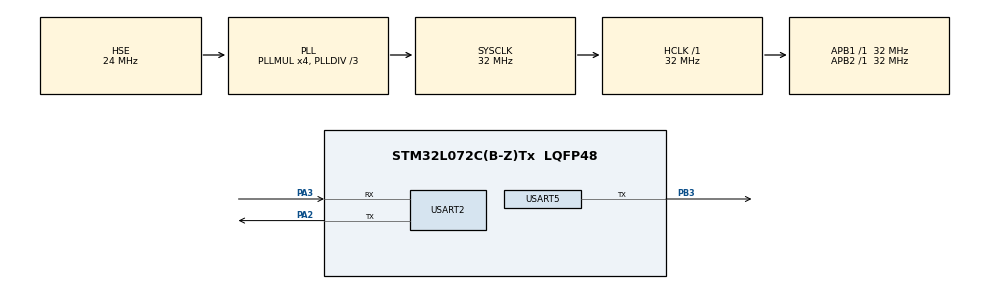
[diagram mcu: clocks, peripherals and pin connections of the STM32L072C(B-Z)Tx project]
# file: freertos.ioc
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Dma.Request0=USART2_RX
Dma.Request1=USART2_TX
Dma.Request2=USART5_TX
Dma.USART2_RX.0.Direction=DMA_PERIPH_TO_MEMORY
Dma.USART2_RX.0.Instance=DMA1_Channel5
Dma.USART2_RX.0.MemDataAlignment=DMA_MDATAALIGN_BYTE
Dma.USART2_RX.0.MemInc=DMA_MINC_ENABLE
Dma.USART2_RX.0.Mode=DMA_CIRCULAR
Dma.USART2_RX.0.PeriphDataAlignment=DMA_PDATAALIGN_BYTE
Dma.USART2_RX.0.PeriphInc=DMA_PINC_DISABLE
Dma.USART2_RX.0.Priority=DMA_PRIORITY_LOW
Dma.USART2_TX.1.Direction=DMA_MEMORY_TO_PERIPH
Dma.USART2_TX.1.Instance=DMA1_Channel4
Dma.USART2_TX.1.MemDataAlignment=DMA_MDATAALIGN_BYTE
Dma.USART2_TX.1.MemInc=DMA_MINC_ENABLE
Dma.USART2_TX.1.Mode=DMA_NORMAL
Dma.USART2_TX.1.PeriphDataAlignment=DMA_PDATAALIGN_BYTE
Dma.USART2_TX.1.PeriphInc=DMA_PINC_DISABLE
Dma.USART2_TX.1.Priority=DMA_PRIORITY_LOW
Dma.USART5_TX.2.Direction=DMA_MEMORY_TO_PERIPH
Dma.USART5_TX.2.Instance=DMA1_Channel3
Dma.USART5_TX.2.MemDataAlignment=DMA_MDATAALIGN_BYTE
Dma.USART5_TX.2.MemInc=DMA_MINC_ENABLE
Dma.USART5_TX.2.Mode=DMA_NORMAL
Dma.USART5_TX.2.PeriphDataAlignment=DMA_PDATAALIGN_BYTE
Dma.USART5_TX.2.PeriphInc=DMA_PINC_DISABLE
Dma.USART5_TX.2.Priority=DMA_PRIORITY_LOW
FREERTOS.BinarySemaphores01=sockfd_sem,Dynamic,NULL,Available
FREERTOS.Tasks01=defaultTask,24,288,StartDefaultTask,Default,NULL,Dynamic,NULL,NULL;publisherTask,24,256,StartPublisherTask,Default,NULL,Dynamic,NULL,NULL
FREERTOS.configGENERATE_RUN_TIME_STATS=1
FREERTOS.configRECORD_STACK_HIGH_ADDRESS=1
FREERTOS.configTOTAL_HEAP_SIZE=12288
FREERTOS.configUSE_STATS_FORMATTING_FUNCTIONS=1
Mcu.Family=STM32L0
Mcu.Name=STM32L072C(B-Z)Tx
Mcu.Package=LQFP48
NVIC.DMA1_Channel2_3_IRQn=true\:3\:0\:false\:false\:true\:true\:false\:true\:true
NVIC.DMA1_Channel4_5_6_7_IRQn=true\:3\:0\:false\:false\:true\:true\:false\:true\:true
NVIC.TIM2_IRQn=true\:3\:0\:false\:false\:true\:false\:false\:true\:true
NVIC.TimeBase=TIM2_IRQn
NVIC.TimeBaseIP=TIM2
NVIC.USART2_IRQn=true\:3\:0\:false\:false\:true\:true\:false\:true\:true
NVIC.USART4_5_IRQn=true\:3\:0\:false\:false\:true\:true\:true\:true\:true
PA2.Mode=Asynchronous
PA2.Signal=USART2_TX
PA3.Mode=Asynchronous
PA3.Signal=USART2_RX
PB3.Mode=Half_duplex(single_wire_mode)
PB3.Signal=USART5_TX
PH0-OSC_IN.Mode=HSE-External-Oscillator
PH0-OSC_IN.Signal=RCC_OSC_IN
PH1-OSC_OUT.Mode=HSE-External-Oscillator
PH1-OSC_OUT.Signal=RCC_OSC_OUT
ProjectManager.HeapSize=0x200
ProjectManager.StackSize=0x400
ProjectManager.TargetToolchain=CMake
RCC.AHBFreq_Value=32000000
RCC.APB1Freq_Value=32000000
RCC.APB1TimFreq_Value=32000000
RCC.APB2Freq_Value=32000000
RCC.APB2TimFreq_Value=32000000
RCC.HCLKFreq_Value=32000000
RCC.HSE_VALUE=24000000
RCC.HSI16_VALUE=16000000
RCC.HSI48_VALUE=48000000
RCC.HSI_VALUE=16000000
RCC.LSE_VALUE=32768
RCC.MSI_VALUE=2097000
RCC.PLLDIV=RCC_PLLDIV_3
RCC.PLLMUL=RCC_PLLMUL_4
RCC.PLLSourceVirtual=RCC_PLLSOURCE_HSE
RCC.SYSCLKFreq_VALUE=32000000
RCC.SYSCLKSource=RCC_SYSCLKSOURCE_PLLCLK
RCC.VCOOutputFreq_Value=96000000
USART2.VirtualMode-Asynchronous=VM_ASYNC
USART5.Mode=MODE_TX
USART5.VirtualMode-Half_duplex(single_wire_mode)=VM_ASYNC
VP_FREERTOS_VS_CMSIS_V2.Mode=CMSIS_V2
VP_SYS_VS_tim2.Mode=TIM2
board=custom

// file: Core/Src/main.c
/* USER CODE BEGIN Header */
/**
 ******************************************************************************
 * @file           : main.c
 * @brief          : Main program body
 ******************************************************************************
 * @attention
 *
 * Copyright (c) 2025 STMicroelectronics.
 * All rights reserved.
 *
 * This software is licensed under terms that can be found in the LICENSE file
 * in the root directory of this software component.
 * If no LICENSE file comes with this software, it is provided AS-IS.
 *
 ******************************************************************************
 */
/* USER CODE END Header */
#include "main.h"
#include "cmsis_os.h"

/* USER CODE BEGIN Includes */
#include <stdio.h>
#include <string.h>
#include <stdlib.h>

#include "umodem.h"
#include "umodem_mqtt.h"
/* USER CODE END Includes */

UART_HandleTypeDef huart2;
UART_HandleTypeDef huart5;
DMA_HandleTypeDef hdma_usart2_rx;
DMA_HandleTypeDef hdma_usart2_tx;
DMA_HandleTypeDef hdma_usart5_tx;

/* Definitions for defaultTask */
osThreadId_t defaultTaskHandle;
const osThreadAttr_t defaultTask_attributes = {
  .name = "defaultTask",
  .stack_size = 288 * 4,
  .priority = (osPriority_t) osPriorityNormal,
};
/* Definitions for publisherTask */
osThreadId_t publisherTaskHandle;
const osThreadAttr_t publisherTask_attributes = {
  .name = "publisherTask",
  .stack_size = 256 * 4,
  .priority = (osPriority_t) osPriorityNormal,
};
/* Definitions for sockfd_sem */
osSemaphoreId_t sockfd_semHandle;
const osSemaphoreAttr_t sockfd_sem_attributes = {
  .name = "sockfd_sem"
};
/* USER CODE BEGIN PV */
static int sockfd = -1;
/* USER CODE END PV */

void SystemClock_Config(void);
static void MX_GPIO_Init(void);
static void MX_DMA_Init(void);
static void MX_USART2_UART_Init(void);
static void MX_USART5_UART_Init(void);
void StartDefaultTask(void *argument);
void StartPublisherTask(void *argument);

/* USER CODE BEGIN 0 */
static osSemaphoreId_t tx5_sem = NULL;
void HAL_UART5_TxCpltCallback(UART_HandleTypeDef *huart)
{
  if (huart->Instance == USART5)
    osSemaphoreRelease(tx5_sem); /* Release the semaphore after the DMA transfer is complete */
}

#ifdef __GNUC__
/* With GCC/RAISONANCE, small printf (option LD Linker->Libraries->Small printf
   set to 'Yes') calls __io_putchar() */
#define PUTCHAR_PROTOTYPE int __io_putchar(int ch)
#else
#define PUTCHAR_PROTOTYPE int fputc(int ch, FILE *f)
#endif /* __GNUC__ */

PUTCHAR_PROTOTYPE
{
  /* Place your implementation of fputc here */
  /* e.g. write a character to the USART5 and Loop until the end of transmission */
  osSemaphoreAcquire(tx5_sem, osWaitForever);
  HAL_UART_Transmit_DMA(&huart5, (uint8_t *)&ch, 1);

  return ch;
}
/* USER CODE END 0 */

int main(void)
{

  /* MCU Configuration--------------------------------------------------------*/

  /* Reset of all peripherals, Initializes the Flash interface and the Systick. */
  HAL_Init();

  /* Configure the system clock */
  SystemClock_Config();

  /* Initialize all configured peripherals */
  MX_GPIO_Init();
  MX_DMA_Init();
  MX_USART2_UART_Init();
  MX_USART5_UART_Init();

  /* Init scheduler */
  osKernelInitialize();

  /* Create the semaphores(s) */
  /* creation of sockfd_sem */
  sockfd_semHandle = osSemaphoreNew(1, 1, &sockfd_sem_attributes);

  /* Create the thread(s) */
  /* creation of defaultTask */
  defaultTaskHandle = osThreadNew(StartDefaultTask, NULL, &defaultTask_attributes);

  /* creation of publisherTask */
  publisherTaskHandle = osThreadNew(StartPublisherTask, NULL, &publisherTask_attributes);

  /* Start scheduler */
  osKernelStart();

  /* We should never get here as control is now taken by the scheduler */

  /* Infinite loop */
  while (1)
  {

  }
}

void SystemClock_Config(void)
{
  RCC_OscInitTypeDef RCC_OscInitStruct = {0};
  RCC_ClkInitTypeDef RCC_ClkInitStruct = {0};
  RCC_PeriphCLKInitTypeDef PeriphClkInit = {0};

  /** Configure the main internal regulator output voltage
  */
  __HAL_PWR_VOLTAGESCALING_CONFIG(PWR_REGULATOR_VOLTAGE_SCALE1);

  /** Initializes the RCC Oscillators according to the specified parameters
  * in the RCC_OscInitTypeDef structure.
  */
  RCC_OscInitStruct.OscillatorType = RCC_OSCILLATORTYPE_HSE;
  RCC_OscInitStruct.HSEState = RCC_HSE_ON;
  RCC_OscInitStruct.PLL.PLLState = RCC_PLL_ON;
  RCC_OscInitStruct.PLL.PLLSource = RCC_PLLSOURCE_HSE;
  RCC_OscInitStruct.PLL.PLLMUL = RCC_PLLMUL_4;
  RCC_OscInitStruct.PLL.PLLDIV = RCC_PLLDIV_3;
  if (HAL_RCC_OscConfig(&RCC_OscInitStruct) != HAL_OK)
  {
    Error_Handler();
  }

  /** Initializes the CPU, AHB and APB buses clocks
  */
  RCC_ClkInitStruct.ClockType = RCC_CLOCKTYPE_HCLK|RCC_CLOCKTYPE_SYSCLK
                              |RCC_CLOCKTYPE_PCLK1|RCC_CLOCKTYPE_PCLK2;
  RCC_ClkInitStruct.SYSCLKSource = RCC_SYSCLKSOURCE_PLLCLK;
  RCC_ClkInitStruct.AHBCLKDivider = RCC_SYSCLK_DIV1;
  RCC_ClkInitStruct.APB1CLKDivider = RCC_HCLK_DIV1;
  RCC_ClkInitStruct.APB2CLKDivider = RCC_HCLK_DIV1;

  if (HAL_RCC_ClockConfig(&RCC_ClkInitStruct, FLASH_LATENCY_1) != HAL_OK)
  {
    Error_Handler();
  }
  PeriphClkInit.PeriphClockSelection = RCC_PERIPHCLK_USART2;
  PeriphClkInit.Usart2ClockSelection = RCC_USART2CLKSOURCE_PCLK1;
  if (HAL_RCCEx_PeriphCLKConfig(&PeriphClkInit) != HAL_OK)
  {
    Error_Handler();
  }
}

static void MX_USART2_UART_Init(void)
{

  huart2.Instance = USART2;
  huart2.Init.BaudRate = 115200;
  huart2.Init.WordLength = UART_WORDLENGTH_8B;
  huart2.Init.StopBits = UART_STOPBITS_1;
  huart2.Init.Parity = UART_PARITY_NONE;
  huart2.Init.Mode = UART_MODE_TX_RX;
  huart2.Init.HwFlowCtl = UART_HWCONTROL_NONE;
  huart2.Init.OverSampling = UART_OVERSAMPLING_16;
  huart2.Init.OneBitSampling = UART_ONE_BIT_SAMPLE_DISABLE;
  huart2.AdvancedInit.AdvFeatureInit = UART_ADVFEATURE_NO_INIT;
  if (HAL_UART_Init(&huart2) != HAL_OK)
  {
    Error_Handler();
  }

}

static void MX_USART5_UART_Init(void)
{

  /* USER CODE BEGIN USART5_Init 0 */
  tx5_sem = osSemaphoreNew(1, 1, NULL);
  if (tx5_sem == NULL)
  {
    Error_Handler();
  }
  /* USER CODE END USART5_Init 0 */

  huart5.Instance = USART5;
  huart5.Init.BaudRate = 115200;
  huart5.Init.WordLength = UART_WORDLENGTH_8B;
  huart5.Init.StopBits = UART_STOPBITS_1;
  huart5.Init.Parity = UART_PARITY_NONE;
  huart5.Init.Mode = UART_MODE_TX;
  huart5.Init.HwFlowCtl = UART_HWCONTROL_NONE;
  huart5.Init.OverSampling = UART_OVERSAMPLING_16;
  huart5.Init.OneBitSampling = UART_ONE_BIT_SAMPLE_DISABLE;
  huart5.AdvancedInit.AdvFeatureInit = UART_ADVFEATURE_NO_INIT;
  if (HAL_HalfDuplex_Init(&huart5) != HAL_OK)
  {
    Error_Handler();
  }
  /* USER CODE BEGIN USART5_Init 2 */
  if (HAL_UART_RegisterCallback(&huart5, HAL_UART_TX_COMPLETE_CB_ID, HAL_UART5_TxCpltCallback) != HAL_OK)
  {
    Error_Handler();
  }
  /* USER CODE END USART5_Init 2 */

}

static void MX_DMA_Init(void)
{

  /* DMA controller clock enable */
  __HAL_RCC_DMA1_CLK_ENABLE();

  /* DMA interrupt init */
  /* DMA1_Channel2_3_IRQn interrupt configuration */
  HAL_NVIC_SetPriority(DMA1_Channel2_3_IRQn, 3, 0);
  HAL_NVIC_EnableIRQ(DMA1_Channel2_3_IRQn);
  /* DMA1_Channel4_5_6_7_IRQn interrupt configuration */
  HAL_NVIC_SetPriority(DMA1_Channel4_5_6_7_IRQn, 3, 0);
  HAL_NVIC_EnableIRQ(DMA1_Channel4_5_6_7_IRQn);

}

static void MX_GPIO_Init(void)
{

  /* GPIO Ports Clock Enable */
  __HAL_RCC_GPIOH_CLK_ENABLE();
  __HAL_RCC_GPIOA_CLK_ENABLE();
  __HAL_RCC_GPIOB_CLK_ENABLE();

}

/* USER CODE BEGIN Header_StartDefaultTask */
/**
 * @brief  Function implementing the defaultTask thread.
 * @param  argument: Not used
 * @retval None
 */
static void on_umodem_event(umodem_event_t* event, void* user_ctx) {
  umodem_event_flag_t event_flag = umodem_event_get_flag(event);
  switch (event_flag) {
  case UMODEM_EVENT_SOCK_CONNECTED: {
    void* event_data = umodem_get_event_data(event);
    printf("Socket connected! on fd %d\n", *(int*)event_data);
    break;
  }
  case UMODEM_EVENT_MQTT_DATA_PUBLISHED: {
    umodem_event_mqtt_data_t* event_data =
        (umodem_event_mqtt_data_t*)umodem_get_event_data(event);
    printf("MQTT message published on fd %d\n", event_data->sockfd);
    break;
  }
  case UMODEM_EVENT_SOCK_CLOSED: printf("Socket closed\n"); break;
  default: break;
  }
}

static umodem_apn_t apn = {
    .apn = "internet",
    .user = "",
    .pass = "",
};
static char imei[16];
static char iccid[24];
static int rssi = 0, ber = 0;
/* USER CODE END Header_StartDefaultTask */
void StartDefaultTask(void *argument)
{
  /* USER CODE BEGIN 5 */
  if (umodem_power_on() != UMODEM_OK)
    Error_Handler();

  if (umodem_init(&apn) != UMODEM_OK)
  {
    printf("Failed to initialize uModem\n");
    umodem_power_off();
    Error_Handler();
  }

  printf("uModem Initialized\n");

  umodem_register_event_callback(on_umodem_event, NULL);

  if (umodem_get_imei(imei, sizeof(imei)) == UMODEM_OK)
    printf("IMEI: %s\n", imei);

  osDelay(pdMS_TO_TICKS(2000)); // wait a bit for signal quality to stabilize

  if (umodem_get_signal_quality(&rssi, &ber) == UMODEM_OK)
    printf("Signal Quality: RSSI=%d, BER=%d\n", rssi, ber);

  if (umodem_get_iccid(iccid, sizeof(iccid)) == UMODEM_OK)
    printf("ICCID: %s\n", iccid);

  if (umodem_mqtt_init() != UMODEM_OK)
    printf("Failed to initialize MQTT\n");
  else
  {
    printf("MQTT Initialized\n");

    umodem_mqtt_will_t will_opts = {
        .topic = "test_topic",
        .message = "any_message",
        .qos = UMODEM_MQTT_QOS_2,
        .retain = 1,
    };
    umodem_mqtt_connect_opts_t opts = {
        .client_id = "testumodem",
        .keepalive = 120,
        .will = &will_opts,
        .delivery_timeout_in_seconds = 5,
        .disable_clean_session = 0,
    };

    if (osSemaphoreAcquire(sockfd_semHandle, osWaitForever) != osOK)
      Error_Handler();

    sockfd = umodem_mqtt_connect("broker.hivemq.com", 1883, &opts);

    osSemaphoreRelease(sockfd_semHandle);

    if (sockfd <= 0)
    {
      printf("Failed to connect MQTT\n");
      umodem_mqtt_deinit();
    }
  }

  /* Infinite loop */
  for (;;)
  {
    umodem_poll();
    osDelay(1);
  }
  /* USER CODE END 5 */
}

void StartPublisherTask(void *argument)
{
  /* USER CODE BEGIN StartPublisherTask */
  // uint8_t count = 0;
  /* Infinite loop */
  for (;;)
  {
    if (osSemaphoreAcquire(sockfd_semHandle, osWaitForever) != osOK)
    {
      osDelay(1);
      continue;
    }

    // if (count < 5 && sockfd > 0)
    if (sockfd > 0)
    {
      // count++;
      char payload[] = "hello_world";
      char topic[] = "test/umodem";
      if (umodem_mqtt_publish(sockfd, topic, sizeof(topic), payload,
              sizeof(payload), UMODEM_MQTT_QOS_2, 0))
        printf("Failed to publish MQTT message.\n");
    }
    osSemaphoreRelease(sockfd_semHandle);

    osDelay(pdMS_TO_TICKS(15000));
  }
  /* USER CODE END StartPublisherTask */
}

void HAL_TIM_PeriodElapsedCallback(TIM_HandleTypeDef *htim)
{
  if (htim->Instance == TIM2)
  {
    HAL_IncTick();
  }
}

void Error_Handler(void)
{
  __disable_irq();
  while (1)
  {
  }
}

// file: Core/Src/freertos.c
/* USER CODE BEGIN Header */
/**
 ******************************************************************************
 * File Name          : freertos.c
 * Description        : Code for freertos applications
 ******************************************************************************
 * @attention
 *
 * Copyright (c) 2025 STMicroelectronics.
 * All rights reserved.
 *
 * This software is licensed under terms that can be found in the LICENSE file
 * in the root directory of this software component.
 * If no LICENSE file comes with this software, it is provided AS-IS.
 *
 ******************************************************************************
 */
/* USER CODE END Header */

#include "FreeRTOS.h"
#include "task.h"
#include "main.h"

/* Hook prototypes */
void configureTimerForRunTimeStats(void);
unsigned long getRunTimeCounterValue(void);

/* USER CODE BEGIN 1 */
/* Functions needed when configGENERATE_RUN_TIME_STATS is on */
__weak void configureTimerForRunTimeStats(void)
{

}

__weak unsigned long getRunTimeCounterValue(void)
{
return 0;
}
/* USER CODE END 1 */
